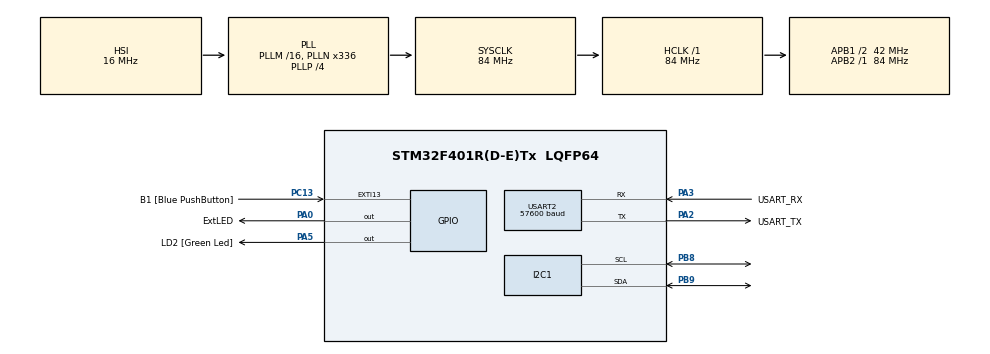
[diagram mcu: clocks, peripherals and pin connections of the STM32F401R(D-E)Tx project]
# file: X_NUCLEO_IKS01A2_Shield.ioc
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Dma.I2C1_RX.2.Direction=DMA_PERIPH_TO_MEMORY
Dma.I2C1_RX.2.FIFOMode=DMA_FIFOMODE_DISABLE
Dma.I2C1_RX.2.Instance=DMA1_Stream0
Dma.I2C1_RX.2.MemDataAlignment=DMA_MDATAALIGN_BYTE
Dma.I2C1_RX.2.MemInc=DMA_MINC_ENABLE
Dma.I2C1_RX.2.Mode=DMA_NORMAL
Dma.I2C1_RX.2.PeriphDataAlignment=DMA_PDATAALIGN_BYTE
Dma.I2C1_RX.2.PeriphInc=DMA_PINC_DISABLE
Dma.I2C1_RX.2.Priority=DMA_PRIORITY_LOW
Dma.I2C1_TX.3.Direction=DMA_MEMORY_TO_PERIPH
Dma.I2C1_TX.3.FIFOMode=DMA_FIFOMODE_DISABLE
Dma.I2C1_TX.3.Instance=DMA1_Stream7
Dma.I2C1_TX.3.MemDataAlignment=DMA_MDATAALIGN_BYTE
Dma.I2C1_TX.3.MemInc=DMA_MINC_ENABLE
Dma.I2C1_TX.3.Mode=DMA_NORMAL
Dma.I2C1_TX.3.PeriphDataAlignment=DMA_PDATAALIGN_BYTE
Dma.I2C1_TX.3.PeriphInc=DMA_PINC_DISABLE
Dma.I2C1_TX.3.Priority=DMA_PRIORITY_LOW
Dma.Request0=USART2_RX
Dma.Request1=USART2_TX
Dma.Request2=I2C1_RX
Dma.Request3=I2C1_TX
Dma.USART2_RX.0.Direction=DMA_PERIPH_TO_MEMORY
Dma.USART2_RX.0.FIFOMode=DMA_FIFOMODE_DISABLE
Dma.USART2_RX.0.Instance=DMA1_Stream5
Dma.USART2_RX.0.MemDataAlignment=DMA_MDATAALIGN_BYTE
Dma.USART2_RX.0.MemInc=DMA_MINC_ENABLE
Dma.USART2_RX.0.Mode=DMA_NORMAL
Dma.USART2_RX.0.PeriphDataAlignment=DMA_PDATAALIGN_BYTE
Dma.USART2_RX.0.PeriphInc=DMA_PINC_DISABLE
Dma.USART2_RX.0.Priority=DMA_PRIORITY_LOW
Dma.USART2_TX.1.Direction=DMA_MEMORY_TO_PERIPH
Dma.USART2_TX.1.FIFOMode=DMA_FIFOMODE_DISABLE
Dma.USART2_TX.1.Instance=DMA1_Stream6
Dma.USART2_TX.1.MemDataAlignment=DMA_MDATAALIGN_BYTE
Dma.USART2_TX.1.MemInc=DMA_MINC_ENABLE
Dma.USART2_TX.1.Mode=DMA_NORMAL
Dma.USART2_TX.1.PeriphDataAlignment=DMA_PDATAALIGN_BYTE
Dma.USART2_TX.1.PeriphInc=DMA_PINC_DISABLE
Dma.USART2_TX.1.Priority=DMA_PRIORITY_LOW
Mcu.Family=STM32F4
Mcu.Name=STM32F401R(D-E)Tx
Mcu.Package=LQFP64
NVIC.DMA1_Stream0_IRQn=true\:0\:0\:false\:false\:true\:false\:true
NVIC.DMA1_Stream5_IRQn=true\:0\:0\:false\:false\:true\:false\:true
NVIC.DMA1_Stream6_IRQn=true\:0\:0\:false\:false\:true\:false\:true
NVIC.DMA1_Stream7_IRQn=true\:0\:0\:false\:false\:true\:false\:true
NVIC.I2C1_ER_IRQn=true\:0\:0\:false\:false\:true\:true\:true
NVIC.I2C1_EV_IRQn=true\:0\:0\:false\:false\:true\:true\:true
NVIC.PriorityGroup=NVIC_PRIORITYGROUP_0
NVIC.TIM3_IRQn=true\:0\:0\:false\:false\:true\:true\:true
NVIC.USART2_IRQn=true\:0\:0\:false\:false\:true\:true\:true
PA0-WKUP.GPIO_Label=ExtLED
PA0-WKUP.GPIO_PuPd=GPIO_NOPULL
PA0-WKUP.Signal=GPIO_Output
PA13.GPIO_Label=TMS
PA13.Mode=Serial_Wire
PA13.Signal=SYS_JTMS-SWDIO
PA14.GPIO_Label=TCK
PA14.Mode=Serial_Wire
PA14.Signal=SYS_JTCK-SWCLK
PA2.GPIO_Label=USART_TX
PA2.GPIO_Mode=GPIO_MODE_AF_PP
PA2.GPIO_PuPd=GPIO_NOPULL
PA2.GPIO_Speed=GPIO_SPEED_FREQ_LOW
PA2.Mode=Asynchronous
PA2.Signal=USART2_TX
PA3.GPIO_Label=USART_RX
PA3.GPIO_Mode=GPIO_MODE_AF_PP
PA3.GPIO_PuPd=GPIO_NOPULL
PA3.GPIO_Speed=GPIO_SPEED_FREQ_LOW
PA3.Mode=Asynchronous
PA3.Signal=USART2_RX
PA5.GPIO_Label=LD2 [Green Led]
PA5.GPIO_Mode=GPIO_MODE_OUTPUT_PP
PA5.GPIO_PuPd=GPIO_NOPULL
PA5.GPIO_Speed=GPIO_SPEED_FREQ_LOW
PA5.Signal=GPIO_Output
PB3.GPIO_Label=SWO
PB3.Signal=SYS_JTDO-SWO
PB8.Mode=I2C
PB8.Signal=I2C1_SCL
PB9.Mode=I2C
PB9.Signal=I2C1_SDA
PC13-ANTI_TAMP.GPIO_Label=B1 [Blue PushButton]
PC13-ANTI_TAMP.GPIO_ModeDefaultEXTI=GPIO_MODE_IT_FALLING
PC13-ANTI_TAMP.GPIO_PuPd=GPIO_NOPULL
PC13-ANTI_TAMP.Signal=GPXTI13
PC14-OSC32_IN.Mode=LSE-External-Clock-Source
PC14-OSC32_IN.Signal=RCC_OSC32_IN
PC15-OSC32_OUT.Mode=LSE-External-Clock-Source
PC15-OSC32_OUT.Signal=RCC_OSC32_OUT
PH0\ -\ OSC_IN.Mode=HSE-External-Oscillator
PH0\ -\ OSC_IN.Signal=RCC_OSC_IN
PH1\ -\ OSC_OUT.Mode=HSE-External-Oscillator
PH1\ -\ OSC_OUT.Signal=RCC_OSC_OUT
ProjectManager.HeapSize=0x200
ProjectManager.StackSize=0x400
ProjectManager.TargetToolchain=STM32CubeIDE
RCC.48MHZClocksFreq_Value=48000000
RCC.AHBFreq_Value=84000000
RCC.APB1CLKDivider=RCC_HCLK_DIV2
RCC.APB1Freq_Value=42000000
RCC.APB1TimFreq_Value=84000000
RCC.APB2Freq_Value=84000000
RCC.APB2TimFreq_Value=84000000
RCC.CortexFreq_Value=84000000
RCC.HCLKFreq_Value=84000000
RCC.HSE_VALUE=8000000
RCC.HSI_VALUE=16000000
RCC.LSE_VALUE=32768
RCC.PLLN=336
RCC.PLLP=RCC_PLLP_DIV4
RCC.PLLQ=7
RCC.SYSCLKFreq_VALUE=84000000
RCC.SYSCLKSource=RCC_SYSCLKSOURCE_PLLCLK
RCC.VCOOutputFreq_Value=336000000
TIM3.Period=10000-1
TIM3.Prescaler=8400-1
USART2.BaudRate=57600
USART2.VirtualMode=VM_ASYNC
VP_TIM3_VS_ClockSourceINT.Mode=Internal
board=NUCLEO-F401RE

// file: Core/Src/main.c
/* USER CODE BEGIN Header */
/**
  ******************************************************************************
  * @file           : main.c
  * @brief          : Main program body
  ******************************************************************************
  * @attention
  *
  * <h2><center>&copy; Copyright (c) 2020 STMicroelectronics.
  * All rights reserved.</center></h2>
  *
  * This software component is licensed by ST under BSD 3-Clause license,
  * the "License"; You may not use this file except in compliance with the
  * License. You may obtain a copy of the License at:
  *                        opensource.org/licenses/BSD-3-Clause
  *
  ******************************************************************************
  */
/* USER CODE END Header */

#include "main.h"

I2C_HandleTypeDef hi2c1;
DMA_HandleTypeDef hdma_i2c1_rx;
DMA_HandleTypeDef hdma_i2c1_tx;

TIM_HandleTypeDef htim3;

UART_HandleTypeDef huart2;
DMA_HandleTypeDef hdma_usart2_rx;
DMA_HandleTypeDef hdma_usart2_tx;

void SystemClock_Config(void);
static void MX_GPIO_Init(void);
static void MX_DMA_Init(void);
static void MX_USART2_UART_Init(void);
static void MX_I2C1_Init(void);
static void MX_TIM3_Init(void);

int main(void)
{

  /* MCU Configuration--------------------------------------------------------*/

  /* Reset of all peripherals, Initializes the Flash interface and the Systick. */
  HAL_Init();

  /* Configure the system clock */
  SystemClock_Config();

  /* Initialize all configured peripherals */
  MX_GPIO_Init();
  MX_DMA_Init();
  MX_USART2_UART_Init();
  MX_I2C1_Init();
  MX_TIM3_Init();
  /* USER CODE BEGIN 2 */
  setup();
  /* USER CODE END 2 */

  /* Infinite loop */
  while (1)
  {

    /* USER CODE BEGIN 3 */
	  loop();
  }
  /* USER CODE END 3 */
}

void SystemClock_Config(void)
{
  RCC_OscInitTypeDef RCC_OscInitStruct = {0};
  RCC_ClkInitTypeDef RCC_ClkInitStruct = {0};

  /** Configure the main internal regulator output voltage
  */
  __HAL_RCC_PWR_CLK_ENABLE();
  __HAL_PWR_VOLTAGESCALING_CONFIG(PWR_REGULATOR_VOLTAGE_SCALE2);
  /** Initializes the CPU, AHB and APB busses clocks
  */
  RCC_OscInitStruct.OscillatorType = RCC_OSCILLATORTYPE_HSI;
  RCC_OscInitStruct.HSIState = RCC_HSI_ON;
  RCC_OscInitStruct.HSICalibrationValue = RCC_HSICALIBRATION_DEFAULT;
  RCC_OscInitStruct.PLL.PLLState = RCC_PLL_ON;
  RCC_OscInitStruct.PLL.PLLSource = RCC_PLLSOURCE_HSI;
  RCC_OscInitStruct.PLL.PLLM = 16;
  RCC_OscInitStruct.PLL.PLLN = 336;
  RCC_OscInitStruct.PLL.PLLP = RCC_PLLP_DIV4;
  RCC_OscInitStruct.PLL.PLLQ = 7;
  if (HAL_RCC_OscConfig(&RCC_OscInitStruct) != HAL_OK)
  {
    Error_Handler();
  }
  /** Initializes the CPU, AHB and APB busses clocks
  */
  RCC_ClkInitStruct.ClockType = RCC_CLOCKTYPE_HCLK|RCC_CLOCKTYPE_SYSCLK
                              |RCC_CLOCKTYPE_PCLK1|RCC_CLOCKTYPE_PCLK2;
  RCC_ClkInitStruct.SYSCLKSource = RCC_SYSCLKSOURCE_PLLCLK;
  RCC_ClkInitStruct.AHBCLKDivider = RCC_SYSCLK_DIV1;
  RCC_ClkInitStruct.APB1CLKDivider = RCC_HCLK_DIV2;
  RCC_ClkInitStruct.APB2CLKDivider = RCC_HCLK_DIV1;

  if (HAL_RCC_ClockConfig(&RCC_ClkInitStruct, FLASH_LATENCY_2) != HAL_OK)
  {
    Error_Handler();
  }
}

static void MX_I2C1_Init(void)
{

  hi2c1.Instance = I2C1;
  hi2c1.Init.ClockSpeed = 100000;
  hi2c1.Init.DutyCycle = I2C_DUTYCYCLE_2;
  hi2c1.Init.OwnAddress1 = 0;
  hi2c1.Init.AddressingMode = I2C_ADDRESSINGMODE_7BIT;
  hi2c1.Init.DualAddressMode = I2C_DUALADDRESS_DISABLE;
  hi2c1.Init.OwnAddress2 = 0;
  hi2c1.Init.GeneralCallMode = I2C_GENERALCALL_DISABLE;
  hi2c1.Init.NoStretchMode = I2C_NOSTRETCH_DISABLE;
  if (HAL_I2C_Init(&hi2c1) != HAL_OK)
  {
    Error_Handler();
  }

}

static void MX_TIM3_Init(void)
{

  TIM_ClockConfigTypeDef sClockSourceConfig = {0};
  TIM_MasterConfigTypeDef sMasterConfig = {0};

  htim3.Instance = TIM3;
  htim3.Init.Prescaler = 8400-1;
  htim3.Init.CounterMode = TIM_COUNTERMODE_UP;
  htim3.Init.Period = 10000-1;
  htim3.Init.ClockDivision = TIM_CLOCKDIVISION_DIV1;
  htim3.Init.AutoReloadPreload = TIM_AUTORELOAD_PRELOAD_DISABLE;
  if (HAL_TIM_Base_Init(&htim3) != HAL_OK)
  {
    Error_Handler();
  }
  sClockSourceConfig.ClockSource = TIM_CLOCKSOURCE_INTERNAL;
  if (HAL_TIM_ConfigClockSource(&htim3, &sClockSourceConfig) != HAL_OK)
  {
    Error_Handler();
  }
  sMasterConfig.MasterOutputTrigger = TIM_TRGO_RESET;
  sMasterConfig.MasterSlaveMode = TIM_MASTERSLAVEMODE_DISABLE;
  if (HAL_TIMEx_MasterConfigSynchronization(&htim3, &sMasterConfig) != HAL_OK)
  {
    Error_Handler();
  }

}

static void MX_USART2_UART_Init(void)
{

  huart2.Instance = USART2;
  huart2.Init.BaudRate = 57600;
  huart2.Init.WordLength = UART_WORDLENGTH_8B;
  huart2.Init.StopBits = UART_STOPBITS_1;
  huart2.Init.Parity = UART_PARITY_NONE;
  huart2.Init.Mode = UART_MODE_TX_RX;
  huart2.Init.HwFlowCtl = UART_HWCONTROL_NONE;
  huart2.Init.OverSampling = UART_OVERSAMPLING_16;
  if (HAL_UART_Init(&huart2) != HAL_OK)
  {
    Error_Handler();
  }

}

static void MX_DMA_Init(void)
{

  /* DMA controller clock enable */
  __HAL_RCC_DMA1_CLK_ENABLE();

  /* DMA interrupt init */
  /* DMA1_Stream0_IRQn interrupt configuration */
  HAL_NVIC_SetPriority(DMA1_Stream0_IRQn, 0, 0);
  HAL_NVIC_EnableIRQ(DMA1_Stream0_IRQn);
  /* DMA1_Stream5_IRQn interrupt configuration */
  HAL_NVIC_SetPriority(DMA1_Stream5_IRQn, 0, 0);
  HAL_NVIC_EnableIRQ(DMA1_Stream5_IRQn);
  /* DMA1_Stream6_IRQn interrupt configuration */
  HAL_NVIC_SetPriority(DMA1_Stream6_IRQn, 0, 0);
  HAL_NVIC_EnableIRQ(DMA1_Stream6_IRQn);
  /* DMA1_Stream7_IRQn interrupt configuration */
  HAL_NVIC_SetPriority(DMA1_Stream7_IRQn, 0, 0);
  HAL_NVIC_EnableIRQ(DMA1_Stream7_IRQn);

}

static void MX_GPIO_Init(void)
{
  GPIO_InitTypeDef GPIO_InitStruct = {0};

  /* GPIO Ports Clock Enable */
  __HAL_RCC_GPIOC_CLK_ENABLE();
  __HAL_RCC_GPIOH_CLK_ENABLE();
  __HAL_RCC_GPIOA_CLK_ENABLE();
  __HAL_RCC_GPIOB_CLK_ENABLE();

  /*Configure GPIO pin Output Level */
  HAL_GPIO_WritePin(GPIOA, ExtLED_Pin|LD2_Pin, GPIO_PIN_RESET);

  /*Configure GPIO pin : B1_Pin */
  GPIO_InitStruct.Pin = B1_Pin;
  GPIO_InitStruct.Mode = GPIO_MODE_IT_FALLING;
  GPIO_InitStruct.Pull = GPIO_NOPULL;
  HAL_GPIO_Init(B1_GPIO_Port, &GPIO_InitStruct);

  /*Configure GPIO pins : ExtLED_Pin LD2_Pin */
  GPIO_InitStruct.Pin = ExtLED_Pin|LD2_Pin;
  GPIO_InitStruct.Mode = GPIO_MODE_OUTPUT_PP;
  GPIO_InitStruct.Pull = GPIO_NOPULL;
  GPIO_InitStruct.Speed = GPIO_SPEED_FREQ_LOW;
  HAL_GPIO_Init(GPIOA, &GPIO_InitStruct);

}

void Error_Handler(void)
{
  /* USER CODE BEGIN Error_Handler_Debug */
  /* User can add his own implementation to report the HAL error return state */
	HAL_GPIO_WritePin(ExtLED_GPIO_Port, ExtLED_Pin, GPIO_PIN_SET);
	while(1);
  /* USER CODE END Error_Handler_Debug */
}

/************************ (C) COPYRIGHT STMicroelectronics *****END OF FILE****/
